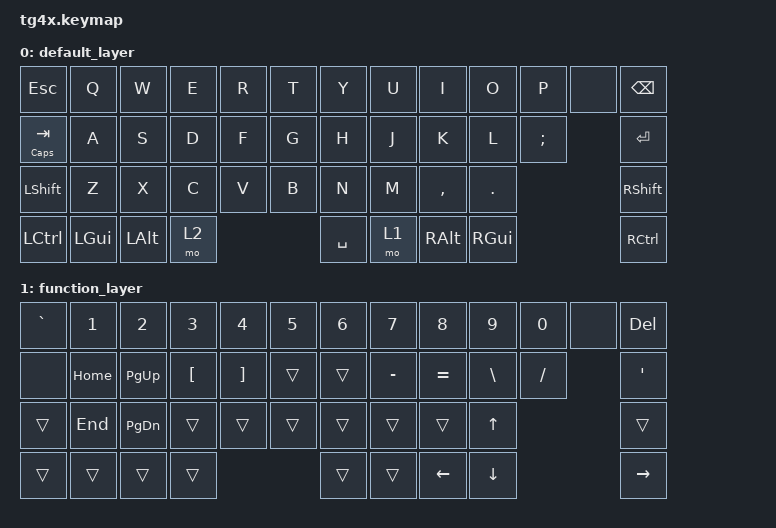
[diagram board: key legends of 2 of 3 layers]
/*
 * Copyright (c) 2020 The ZMK Contributors
 *
 * SPDX-License-Identifier: MIT
 */

#include <behaviors.dtsi>
#include <dt-bindings/zmk/keys.h>
#include <dt-bindings/zmk/bt.h>

&led_strip {
    chain-length = <1>;
};

/ {
	behaviors {
		ht: hold_tap {
			compatible = "zmk,behavior-hold-tap";
			label = "Hold Tap";
			#binding-cells = <2>;
			tapping_term_ms = <200>;
			flavor = "tap-preferred";
			bindings = <&kp>, <&kp>;
		};
	};

	keymap {
		compatible = "zmk,keymap";

		default_layer {
			bindings = <
&kp ESC      &kp Q    &kp W    &kp E &kp R &kp T &kp Y     &kp U &kp I     &kp O    &kp P    &none &kp BSPC
&ht CAPS TAB &kp A    &kp S    &kp D &kp F &kp G &kp H     &kp J &kp K     &kp L    &kp SEMI       &kp RET
&kp LSHFT    &kp Z    &kp X    &kp C &kp V &kp B &kp N     &kp M &kp COMMA &kp DOT                 &kp RSHFT
&kp LCTRL    &kp LGUI &kp LALT &mo 2             &kp SPACE &mo 1 &kp RALT  &kp RGUI                &kp RCTRL
			>;
		};

		function_layer {
			bindings = <
&kp GRAVE &kp N1   &kp N2    &kp N3   &kp N4   &kp N5 &kp N6   &kp N7    &kp N8    &kp N9    &kp N0   &none &kp DEL
&none     &kp HOME &kp PG_UP &kp LBKT &kp RBKT &trans &trans   &kp MINUS &kp EQUAL &kp BSLH  &kp FSLH       &kp APOS
&trans    &kp END  &kp PG_DN &trans   &trans &trans   &trans   &trans    &trans    &kp UP                   &trans
&trans    &trans   &trans    &trans                            &trans    &trans    &kp LEFT  &kp DOWN       &kp RIGHT
			>;
		};

		other_layer {
			bindings = <
&kp F1 &kp F2     &kp F3     &kp F4 &kp F5 &kp F6 &kp F7 &kp F8       &kp F9       &kp F10    &kp F11 &none &kp F12
&trans &trans     &trans     &trans     &trans &trans &trans &trans &trans       &trans       &trans        &kp INSERT
&trans &bt BT_CLR &bt BT_PRV &bt BT_NXT &trans &trans &trans &trans &bootloader  &reset                     &kp PRINTSCREEN
&trans &trans     &trans     &trans                          &trans &kp C_VOL_UP &kp C_VOL_DN               &kp C_PP
			>;
		};

	};
};
